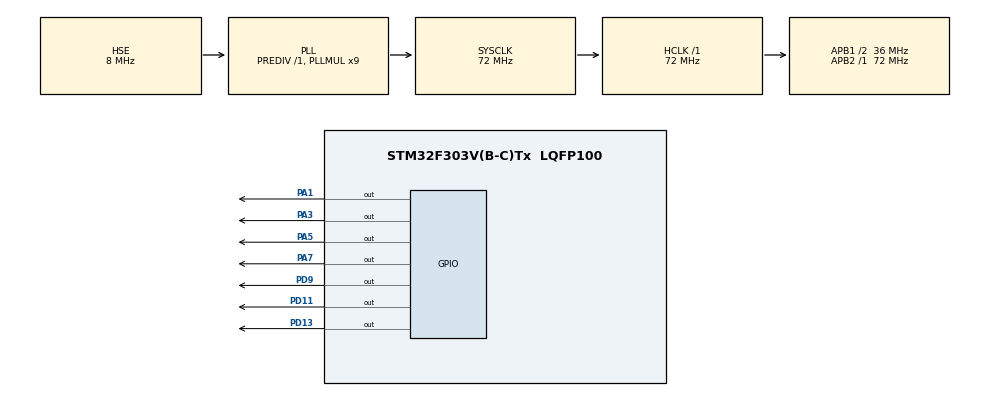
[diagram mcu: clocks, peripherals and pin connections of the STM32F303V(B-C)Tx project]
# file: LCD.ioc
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Mcu.Family=STM32F3
Mcu.Name=STM32F303V(B-C)Tx
Mcu.Package=LQFP100
NVIC.PriorityGroup=NVIC_PRIORITYGROUP_4
PA1.Signal=GPIO_Output
PA13.Mode=Serial_Wire
PA13.Signal=SYS_JTMS-SWDIO
PA14.Mode=Serial_Wire
PA14.Signal=SYS_JTCK-SWCLK
PA3.Signal=GPIO_Output
PA5.Signal=GPIO_Output
PA7.Signal=GPIO_Output
PD11.Signal=GPIO_Output
PD13.Signal=GPIO_Output
PD9.Signal=GPIO_Output
PF0-OSC_IN.Mode=HSE-External-Oscillator
PF0-OSC_IN.Signal=RCC_OSC_IN
PF1-OSC_OUT.Mode=HSE-External-Oscillator
PF1-OSC_OUT.Signal=RCC_OSC_OUT
ProjectManager.HeapSize=0x200
ProjectManager.StackSize=0x400
ProjectManager.TargetToolchain=STM32CubeIDE
RCC.AHBFreq_Value=72000000
RCC.APB1CLKDivider=RCC_HCLK_DIV2
RCC.APB1Freq_Value=36000000
RCC.APB1TimFreq_Value=72000000
RCC.APB2Freq_Value=72000000
RCC.APB2TimFreq_Value=72000000
RCC.CortexFreq_Value=72000000
RCC.HCLKFreq_Value=72000000
RCC.HSE_VALUE=8000000
RCC.HSI_VALUE=8000000
RCC.LSE_VALUE=32768
RCC.PLLMUL=RCC_PLL_MUL9
RCC.PLLSourceVirtual=RCC_PLLSOURCE_HSE
RCC.SYSCLKFreq_VALUE=72000000
RCC.SYSCLKSourceVirtual=RCC_SYSCLKSOURCE_PLLCLK
RCC.USBFreq_Value=72000000
TIM1.Period=0xffff-1
TIM1.Prescaler=72-1
VP_TIM1_VS_ClockSourceINT.Mode=Internal
board=custom

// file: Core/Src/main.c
/* USER CODE BEGIN Header */
/**
  ******************************************************************************
  * @file           : main.c
  * @brief          : Main program body
  ******************************************************************************
  * @attention
  *
  * Copyright (c) 2024 STMicroelectronics.
  * All rights reserved.
  *
  * This software is licensed under terms that can be found in the LICENSE file
  * in the root directory of this software component.
  * If no LICENSE file comes with this software, it is provided AS-IS.
  *
  ******************************************************************************
  */
/* USER CODE END Header */
#include "main.h"

/* USER CODE BEGIN Includes */
#include "LCD.h"
/* USER CODE END Includes */

TIM_HandleTypeDef htim1;

void SystemClock_Config(void);
static void MX_GPIO_Init(void);
static void MX_TIM1_Init(void);

/* USER CODE BEGIN 0 */
//int row=0;
//int col=0;
/* USER CODE END 0 */

int main(void)
{

  /* MCU Configuration--------------------------------------------------------*/

  /* Reset of all peripherals, Initializes the Flash interface and the Systick. */
  HAL_Init();

  /* Configure the system clock */
  SystemClock_Config();

  /* Initialize all configured peripherals */
  MX_GPIO_Init();
  MX_TIM1_Init();
  /* USER CODE BEGIN 2 */

  lcd_init();

  /* USER CODE END 2 */

  /* Infinite loop */
  while (1)
  {

    /* USER CODE BEGIN 3 */
	  lcd_put_cur(0, 0);
	 		 	   lcd_send_string("Hello ");
	 		 	   lcd_send_string("Engr ");
	 		 	  lcd_send_string("Fazal ");
	 		 	   lcd_put_cur(1, 0);
	 		 	   lcd_send_string("Chip Soul SMC");
	 		 	   HAL_Delay(3000);
	 		 	 lcd_clear();
//	  for (int i=0;i<128;i++)
//	  {
//		  lcd_put_cur(row, col);
//		  lcd_send_data(i+48);
//		  col++;
//		  if (col > 15) {row++; col= 0;}
//		  if (row > 1) row=0;
//		  HAL_Delay(250);
//	  }
  }
  /* USER CODE END 3 */
}

void SystemClock_Config(void)
{
  RCC_OscInitTypeDef RCC_OscInitStruct = {0};
  RCC_ClkInitTypeDef RCC_ClkInitStruct = {0};
  RCC_PeriphCLKInitTypeDef PeriphClkInit = {0};

  /** Initializes the RCC Oscillators according to the specified parameters
  * in the RCC_OscInitTypeDef structure.
  */
  RCC_OscInitStruct.OscillatorType = RCC_OSCILLATORTYPE_HSE;
  RCC_OscInitStruct.HSEState = RCC_HSE_ON;
  RCC_OscInitStruct.HSEPredivValue = RCC_HSE_PREDIV_DIV1;
  RCC_OscInitStruct.HSIState = RCC_HSI_ON;
  RCC_OscInitStruct.PLL.PLLState = RCC_PLL_ON;
  RCC_OscInitStruct.PLL.PLLSource = RCC_PLLSOURCE_HSE;
  RCC_OscInitStruct.PLL.PLLMUL = RCC_PLL_MUL9;
  if (HAL_RCC_OscConfig(&RCC_OscInitStruct) != HAL_OK)
  {
    Error_Handler();
  }

  /** Initializes the CPU, AHB and APB buses clocks
  */
  RCC_ClkInitStruct.ClockType = RCC_CLOCKTYPE_HCLK|RCC_CLOCKTYPE_SYSCLK
                              |RCC_CLOCKTYPE_PCLK1|RCC_CLOCKTYPE_PCLK2;
  RCC_ClkInitStruct.SYSCLKSource = RCC_SYSCLKSOURCE_PLLCLK;
  RCC_ClkInitStruct.AHBCLKDivider = RCC_SYSCLK_DIV1;
  RCC_ClkInitStruct.APB1CLKDivider = RCC_HCLK_DIV2;
  RCC_ClkInitStruct.APB2CLKDivider = RCC_HCLK_DIV1;

  if (HAL_RCC_ClockConfig(&RCC_ClkInitStruct, FLASH_LATENCY_2) != HAL_OK)
  {
    Error_Handler();
  }
  PeriphClkInit.PeriphClockSelection = RCC_PERIPHCLK_TIM1;
  PeriphClkInit.Tim1ClockSelection = RCC_TIM1CLK_HCLK;
  if (HAL_RCCEx_PeriphCLKConfig(&PeriphClkInit) != HAL_OK)
  {
    Error_Handler();
  }
}

static void MX_TIM1_Init(void)
{

  TIM_ClockConfigTypeDef sClockSourceConfig = {0};
  TIM_MasterConfigTypeDef sMasterConfig = {0};

  htim1.Instance = TIM1;
  htim1.Init.Prescaler = 72-1;
  htim1.Init.CounterMode = TIM_COUNTERMODE_UP;
  htim1.Init.Period = 0xffff-1;
  htim1.Init.ClockDivision = TIM_CLOCKDIVISION_DIV1;
  htim1.Init.RepetitionCounter = 0;
  htim1.Init.AutoReloadPreload = TIM_AUTORELOAD_PRELOAD_DISABLE;
  if (HAL_TIM_Base_Init(&htim1) != HAL_OK)
  {
    Error_Handler();
  }
  sClockSourceConfig.ClockSource = TIM_CLOCKSOURCE_INTERNAL;
  if (HAL_TIM_ConfigClockSource(&htim1, &sClockSourceConfig) != HAL_OK)
  {
    Error_Handler();
  }
  sMasterConfig.MasterOutputTrigger = TIM_TRGO_RESET;
  sMasterConfig.MasterOutputTrigger2 = TIM_TRGO2_RESET;
  sMasterConfig.MasterSlaveMode = TIM_MASTERSLAVEMODE_DISABLE;
  if (HAL_TIMEx_MasterConfigSynchronization(&htim1, &sMasterConfig) != HAL_OK)
  {
    Error_Handler();
  }

}

static void MX_GPIO_Init(void)
{
  GPIO_InitTypeDef GPIO_InitStruct = {0};

  /* GPIO Ports Clock Enable */
  __HAL_RCC_GPIOF_CLK_ENABLE();
  __HAL_RCC_GPIOA_CLK_ENABLE();
  __HAL_RCC_GPIOD_CLK_ENABLE();

  /*Configure GPIO pin Output Level */
  HAL_GPIO_WritePin(GPIOA, GPIO_PIN_1|GPIO_PIN_3|GPIO_PIN_5|GPIO_PIN_7, GPIO_PIN_RESET);

  /*Configure GPIO pin Output Level */
  HAL_GPIO_WritePin(GPIOD, GPIO_PIN_9|GPIO_PIN_11|GPIO_PIN_13, GPIO_PIN_RESET);

  /*Configure GPIO pins : PA1 PA3 PA5 PA7 */
  GPIO_InitStruct.Pin = GPIO_PIN_1|GPIO_PIN_3|GPIO_PIN_5|GPIO_PIN_7;
  GPIO_InitStruct.Mode = GPIO_MODE_OUTPUT_PP;
  GPIO_InitStruct.Pull = GPIO_NOPULL;
  GPIO_InitStruct.Speed = GPIO_SPEED_FREQ_LOW;
  HAL_GPIO_Init(GPIOA, &GPIO_InitStruct);

  /*Configure GPIO pins : PD9 PD11 PD13 */
  GPIO_InitStruct.Pin = GPIO_PIN_9|GPIO_PIN_11|GPIO_PIN_13;
  GPIO_InitStruct.Mode = GPIO_MODE_OUTPUT_PP;
  GPIO_InitStruct.Pull = GPIO_NOPULL;
  GPIO_InitStruct.Speed = GPIO_SPEED_FREQ_LOW;
  HAL_GPIO_Init(GPIOD, &GPIO_InitStruct);

}

void Error_Handler(void)
{
  __disable_irq();
  while (1)
  {
  }
}
